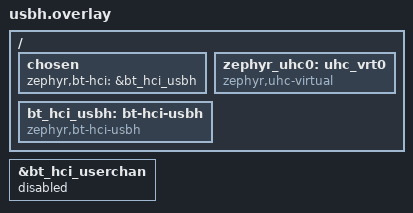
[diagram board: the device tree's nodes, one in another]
/*
 * SPDX-FileCopyrightText: Copyright The Zephyr Project Contributors
 * SPDX-License-Identifier: Apache-2.0
 */

/delete-node/ &zephyr_udc0;

/ {
	chosen {
		zephyr,bt-hci = &bt_hci_usbh;
	};

	zephyr_uhc0: uhc_vrt0 {
		compatible = "zephyr,uhc-virtual";
	};

	bt_hci_usbh: bt-hci-usbh {
		compatible = "zephyr,bt-hci-usbh";
		status = "okay";
	};
};

&bt_hci_userchan {
	status = "disabled";
};
